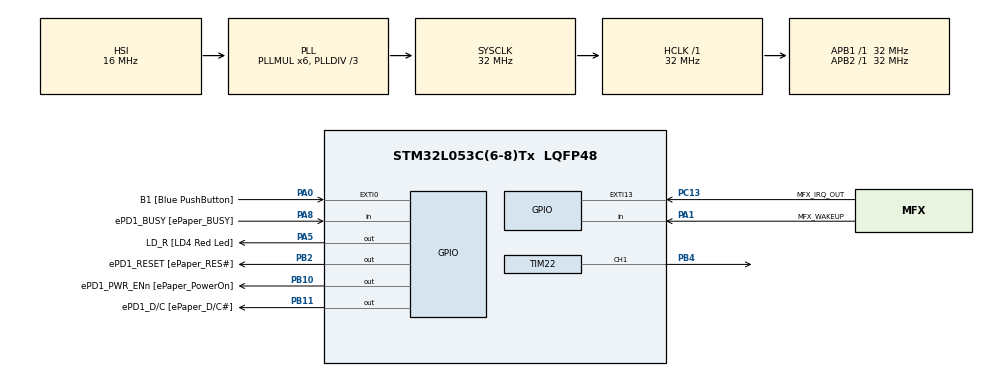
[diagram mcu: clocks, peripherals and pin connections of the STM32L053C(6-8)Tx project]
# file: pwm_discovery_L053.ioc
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Mcu.Family=STM32L0
Mcu.Name=STM32L053C(6-8)Tx
Mcu.Package=LQFP48
PA0.GPIO_Label=B1 [Blue PushButton]
PA0.GPIO_ModeDefaultEXTI=GPIO_MODE_EVT_RISING
PA0.GPIO_PuPd=GPIO_NOPULL
PA0.Signal=GPXTI0
PA1.GPIO_Label=MFX_WAKEUP
PA1.Signal=GPIO_Input
PA10.GPIO_Label=USART_RX
PA10.Signal=USART1_RX
PA11.GPIO_Label=USB1_DM
PA11.Signal=USB_DM
PA12.GPIO_Label=USB1_DP
PA12.Signal=USB_DP
PA13.GPIO_Label=SWDIO
PA13.Signal=SYS_SWDIO
PA15.GPIO_Label=ePD1_CS [ePaper_CS\#]
PA15.GPIO_Mode=GPIO_MODE_AF_PP
PA15.GPIO_PuPd=GPIO_NOPULL
PA15.GPIO_Speed=GPIO_SPEED_LOW
PA15.Signal=SPI1_NSS
PA2.Signal=TSC_G1_IO3
PA3.Signal=TSC_G1_IO4
PA5.GPIO_Label=LD_R [LD4 Red Led]
PA5.GPIO_ModeDefaultOutputPP=GPIO_MODE_OUTPUT_PP
PA5.GPIO_PuPd=GPIO_NOPULL
PA5.GPIO_Speed=GPIO_SPEED_LOW
PA5.Signal=GPIO_Output
PA6.Signal=TSC_G2_IO3
PA7.Signal=TSC_G2_IO4
PA8.GPIO_Label=ePD1_BUSY [ePaper_BUSY]
PA8.GPIO_Mode=GPIO_MODE_INPUT
PA8.GPIO_PuPd=GPIO_NOPULL
PA8.Signal=GPIO_Input
PA9.GPIO_Label=USART_TX
PA9.Signal=USART1_TX
PB0.Signal=TSC_G3_IO2
PB1.Signal=TSC_G3_IO3
PB10.GPIO_Label=ePD1_PWR_ENn [ePaper_PowerOn]
PB10.GPIO_ModeDefaultOutputPP=GPIO_MODE_OUTPUT_PP
PB10.GPIO_PuPd=GPIO_NOPULL
PB10.GPIO_Speed=GPIO_SPEED_LOW
PB10.Signal=GPIO_Output
PB11.GPIO_Label=ePD1_D/C [ePaper_D/C\#]
PB11.GPIO_ModeDefaultOutputPP=GPIO_MODE_OUTPUT_PP
PB11.GPIO_PuPd=GPIO_NOPULL
PB11.GPIO_Speed=GPIO_SPEED_LOW
PB11.Signal=GPIO_Output
PB12.GPIO_Label=NFC_NSS
PB12.Signal=SPI2_NSS
PB13.GPIO_Label=NFC_SCK
PB13.Signal=SPI2_SCK
PB14.GPIO_Label=NFC_MISO
PB14.Signal=SPI2_MISO
PB15.GPIO_Label=NFC_MOSI
PB15.Signal=SPI2_MOSI
PB2.GPIO_Label=ePD1_RESET [ePaper_RES\#]
PB2.GPIO_ModeDefaultOutputPP=GPIO_MODE_OUTPUT_PP
PB2.GPIO_PuPd=GPIO_NOPULL
PB2.GPIO_Speed=GPIO_SPEED_LOW
PB2.Signal=GPIO_Output
PB3.GPIO_Label=ePD1_SCK [ePaper_SCK]
PB3.GPIO_Mode=GPIO_MODE_AF_PP
PB3.GPIO_PuPd=GPIO_NOPULL
PB3.GPIO_Speed=GPIO_SPEED_LOW
PB3.Signal=SPI1_SCK
PB4.Signal=S_TIM22_CH1
PB5.GPIO_Label=ePD1_MOSI [ePaper_MOSI]
PB5.GPIO_Mode=GPIO_MODE_AF_PP
PB5.GPIO_PuPd=GPIO_NOPULL
PB5.GPIO_Speed=GPIO_SPEED_LOW
PB5.Signal=SPI1_MOSI
PB8.GPIO_Label=MFX_I2C_SCL
PB8.Signal=I2C1_SCL
PB9.GPIO_Label=MFX_I2C_SDA
PB9.Signal=I2C1_SDA
PC13.GPIO_Label=MFX_IRQ_OUT
PC13.Signal=GPXTI13
PC14-OSC32_IN.GPIO_Label=PC14-OSC32_IN
PC14-OSC32_IN.Signal=RCC_OSC32_IN
PC15-OSC32_OUT.GPIO_Label=PC15-OSC32_OUT
PC15-OSC32_OUT.Signal=RCC_OSC32_OUT
PH0-OSC_IN.GPIO_Label=MCO
PH0-OSC_IN.Signal=RCC_OSC_IN
ProjectManager.TargetToolchain=MDK-ARM V5
RCC.AHBFreq_Value=32000000
RCC.APB1Freq_Value=32000000
RCC.APB1TimFreq_Value=32000000
RCC.APB2Freq_Value=32000000
RCC.APB2TimFreq_Value=32000000
RCC.HCLKFreq_Value=32000000
RCC.HSE_VALUE=8000000
RCC.HSI16_VALUE=16000000
RCC.HSI48MClockSelection=RCC_USBCLKSOURCE_HSI48
RCC.HSI48_VALUE=48000000
RCC.HSI_VALUE=16000000
RCC.LSE_VALUE=32768
RCC.MSI_VALUE=2097000
RCC.PLLDIV=RCC_PLLDIV_3
RCC.PLLMUL=RCC_PLLMUL_6
RCC.RTCClockSelectionVirtual=RCC_RTCCLKSOURCE_LSE
RCC.SYSCLKFreq_VALUE=32000000
RCC.SYSCLKSource=RCC_SYSCLKSOURCE_PLLCLK
RCC.VCOOutputFreq_Value=96000000
SH.S_TIM22_CH1.0=TIM22_CH1,PWM Generation1 CH1
TIM22.Period=200
TIM22.Prescaler=32000
VP_TIM22_VS_ClockSourceINT.Mode=Internal
board=STM32L0538DISCOVERY

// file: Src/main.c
/**
  ******************************************************************************
  * File Name          : main.c
  * Description        : Main program body
  ******************************************************************************
  *
  * COPYRIGHT(c) 2015 STMicroelectronics
  *
  * Redistribution and use in source and binary forms, with or without modification,
  * are permitted provided that the following conditions are met:
  *   1. Redistributions of source code must retain the above copyright notice,
  *      this list of conditions and the following disclaimer.
  *   2. Redistributions in binary form must reproduce the above copyright notice,
  *      this list of conditions and the following disclaimer in the documentation
  *      and/or other materials provided with the distribution.
  *   3. Neither the name of STMicroelectronics nor the names of its contributors
  *      may be used to endorse or promote products derived from this software
  *      without specific prior written permission.
  *
  * THIS SOFTWARE IS PROVIDED BY THE COPYRIGHT HOLDERS AND CONTRIBUTORS "AS IS"
  * AND ANY EXPRESS OR IMPLIED WARRANTIES, INCLUDING, BUT NOT LIMITED TO, THE
  * IMPLIED WARRANTIES OF MERCHANTABILITY AND FITNESS FOR A PARTICULAR PURPOSE ARE
  * DISCLAIMED. IN NO EVENT SHALL THE COPYRIGHT HOLDER OR CONTRIBUTORS BE LIABLE
  * FOR ANY DIRECT, INDIRECT, INCIDENTAL, SPECIAL, EXEMPLARY, OR CONSEQUENTIAL
  * DAMAGES (INCLUDING, BUT NOT LIMITED TO, PROCUREMENT OF SUBSTITUTE GOODS OR
  * SERVICES; LOSS OF USE, DATA, OR PROFITS; OR BUSINESS INTERRUPTION) HOWEVER
  * CAUSED AND ON ANY THEORY OF LIABILITY, WHETHER IN CONTRACT, STRICT LIABILITY,
  * OR TORT (INCLUDING NEGLIGENCE OR OTHERWISE) ARISING IN ANY WAY OUT OF THE USE
  * OF THIS SOFTWARE, EVEN IF ADVISED OF THE POSSIBILITY OF SUCH DAMAGE.
  *
  ******************************************************************************
  */
#include "stm32l0xx_hal.h"

TIM_HandleTypeDef htim22;

/* USER CODE BEGIN PV */
/* Private variables ---------------------------------------------------------*/
int pwm = 0;
/* USER CODE END PV */

void SystemClock_Config(void);
static void MX_GPIO_Init(void);
static void MX_TIM22_Init(void);

/* USER CODE BEGIN PFP */
/* Private function prototypes -----------------------------------------------*/

/* USER CODE END PFP */

/* USER CODE BEGIN 0 */
void HAL_TIM_PeriodElapsedCallback(TIM_HandleTypeDef *htim)
{
}
/* USER CODE END 0 */

int main(void)
{

  /* MCU Configuration----------------------------------------------------------*/

  /* Reset of all peripherals, Initializes the Flash interface and the Systick. */
  HAL_Init();

  /* Configure the system clock */
  SystemClock_Config();

  /* Initialize all configured peripherals */
  MX_GPIO_Init();
  MX_TIM22_Init();

  /* USER CODE BEGIN 2 */
  HAL_TIM_PWM_Start(&htim22, TIM_CHANNEL_1);
  /* USER CODE END 2 */

  /* Infinite loop */
  while (1)
  {

  /* USER CODE BEGIN 3 */

    __HAL_TIM_SetCompare(&htim22, TIM_CHANNEL_1, 150);
    HAL_Delay(4000);
    __HAL_TIM_SetCompare(&htim22, TIM_CHANNEL_1, 50);
    HAL_Delay(4000);

  }
  /* USER CODE END 3 */

}

/** System Clock Configuration
*/
void SystemClock_Config(void)
{

  RCC_OscInitTypeDef RCC_OscInitStruct;
  RCC_ClkInitTypeDef RCC_ClkInitStruct;

  __PWR_CLK_ENABLE();

  __HAL_PWR_VOLTAGESCALING_CONFIG(PWR_REGULATOR_VOLTAGE_SCALE1);

  RCC_OscInitStruct.OscillatorType = RCC_OSCILLATORTYPE_HSI;
  RCC_OscInitStruct.HSIState = RCC_HSI_ON;
  RCC_OscInitStruct.HSICalibrationValue = 16;
  RCC_OscInitStruct.PLL.PLLState = RCC_PLL_ON;
  RCC_OscInitStruct.PLL.PLLSource = RCC_PLLSOURCE_HSI;
  RCC_OscInitStruct.PLL.PLLMUL = RCC_PLLMUL_6;
  RCC_OscInitStruct.PLL.PLLDIV = RCC_PLLDIV_3;
  HAL_RCC_OscConfig(&RCC_OscInitStruct);

  RCC_ClkInitStruct.ClockType = RCC_CLOCKTYPE_SYSCLK;
  RCC_ClkInitStruct.SYSCLKSource = RCC_SYSCLKSOURCE_PLLCLK;
  RCC_ClkInitStruct.AHBCLKDivider = RCC_SYSCLK_DIV1;
  RCC_ClkInitStruct.APB1CLKDivider = RCC_HCLK_DIV1;
  RCC_ClkInitStruct.APB2CLKDivider = RCC_HCLK_DIV1;
  HAL_RCC_ClockConfig(&RCC_ClkInitStruct, FLASH_LATENCY_1);

  HAL_SYSTICK_Config(HAL_RCC_GetHCLKFreq()/1000);

  HAL_SYSTICK_CLKSourceConfig(SYSTICK_CLKSOURCE_HCLK);

  /* SysTick_IRQn interrupt configuration */
  HAL_NVIC_SetPriority(SysTick_IRQn, 0, 0);
}

/* TIM22 init function */
void MX_TIM22_Init(void)
{

  TIM_ClockConfigTypeDef sClockSourceConfig;
  TIM_MasterConfigTypeDef sMasterConfig;
  TIM_OC_InitTypeDef sConfigOC;

  htim22.Instance = TIM22;
  htim22.Init.Prescaler = 320;
  htim22.Init.CounterMode = TIM_COUNTERMODE_UP;
  htim22.Init.Period = 200;
  htim22.Init.ClockDivision = TIM_CLOCKDIVISION_DIV1;
  HAL_TIM_Base_Init(&htim22);

  sClockSourceConfig.ClockSource = TIM_CLOCKSOURCE_INTERNAL;
  HAL_TIM_ConfigClockSource(&htim22, &sClockSourceConfig);

  HAL_TIM_PWM_Init(&htim22);

  sMasterConfig.MasterOutputTrigger = TIM_TRGO_RESET;
  sMasterConfig.MasterSlaveMode = TIM_MASTERSLAVEMODE_DISABLE;
  HAL_TIMEx_MasterConfigSynchronization(&htim22, &sMasterConfig);

  sConfigOC.OCMode = TIM_OCMODE_PWM1;
  sConfigOC.Pulse = 0;
  sConfigOC.OCPolarity = TIM_OCPOLARITY_HIGH;
  sConfigOC.OCFastMode = TIM_OCFAST_DISABLE;
  HAL_TIM_PWM_ConfigChannel(&htim22, &sConfigOC, TIM_CHANNEL_1);

}

/** Configure pins as
        * Analog
        * Input
        * Output
        * EVENT_OUT
        * EXTI
     PA2   ------> TSC_G1_IO3
     PA3   ------> TSC_G1_IO4
     PA6   ------> TSC_G2_IO3
     PA7   ------> TSC_G2_IO4
     PB0   ------> TSC_G3_IO2
     PB1   ------> TSC_G3_IO3
     PB12   ------> SPI2_NSS
     PB13   ------> SPI2_SCK
     PB14   ------> SPI2_MISO
     PB15   ------> SPI2_MOSI
     PA9   ------> USART1_TX
     PA10   ------> USART1_RX
     PA15   ------> SPI1_NSS
     PB3   ------> SPI1_SCK
     PB5   ------> SPI1_MOSI
     PB8   ------> I2C1_SCL
     PB9   ------> I2C1_SDA
*/
void MX_GPIO_Init(void)
{

  GPIO_InitTypeDef GPIO_InitStruct;

  /* GPIO Ports Clock Enable */
  __GPIOC_CLK_ENABLE();
  __GPIOH_CLK_ENABLE();
  __GPIOA_CLK_ENABLE();
  __GPIOB_CLK_ENABLE();

  /*Configure GPIO pin : MFX_IRQ_OUT_Pin */
  GPIO_InitStruct.Pin = MFX_IRQ_OUT_Pin;
  GPIO_InitStruct.Mode = GPIO_MODE_IT_RISING;
  GPIO_InitStruct.Pull = GPIO_NOPULL;
  HAL_GPIO_Init(MFX_IRQ_OUT_GPIO_Port, &GPIO_InitStruct);

  /*Configure GPIO pin : B1_Pin */
  GPIO_InitStruct.Pin = B1_Pin;
  GPIO_InitStruct.Mode = GPIO_MODE_EVT_RISING;
  GPIO_InitStruct.Pull = GPIO_NOPULL;
  HAL_GPIO_Init(B1_GPIO_Port, &GPIO_InitStruct);

  /*Configure GPIO pins : MFX_WAKEUP_Pin ePD1_BUSY_Pin */
  GPIO_InitStruct.Pin = MFX_WAKEUP_Pin|ePD1_BUSY_Pin;
  GPIO_InitStruct.Mode = GPIO_MODE_INPUT;
  GPIO_InitStruct.Pull = GPIO_NOPULL;
  HAL_GPIO_Init(GPIOA, &GPIO_InitStruct);

  /*Configure GPIO pins : PA2 PA3 PA6 PA7 */
  GPIO_InitStruct.Pin = GPIO_PIN_2|GPIO_PIN_3|GPIO_PIN_6|GPIO_PIN_7;
  GPIO_InitStruct.Mode = GPIO_MODE_AF_PP;
  GPIO_InitStruct.Pull = GPIO_NOPULL;
  GPIO_InitStruct.Speed = GPIO_SPEED_LOW;
  GPIO_InitStruct.Alternate = GPIO_AF3_TSC;
  HAL_GPIO_Init(GPIOA, &GPIO_InitStruct);

  /*Configure GPIO pin : LD_R_Pin */
  GPIO_InitStruct.Pin = LD_R_Pin;
  GPIO_InitStruct.Mode = GPIO_MODE_OUTPUT_PP;
  GPIO_InitStruct.Pull = GPIO_NOPULL;
  GPIO_InitStruct.Speed = GPIO_SPEED_LOW;
  HAL_GPIO_Init(LD_R_GPIO_Port, &GPIO_InitStruct);

  /*Configure GPIO pins : PB0 PB1 */
  GPIO_InitStruct.Pin = GPIO_PIN_0|GPIO_PIN_1;
  GPIO_InitStruct.Mode = GPIO_MODE_AF_PP;
  GPIO_InitStruct.Pull = GPIO_NOPULL;
  GPIO_InitStruct.Speed = GPIO_SPEED_LOW;
  GPIO_InitStruct.Alternate = GPIO_AF3_TSC;
  HAL_GPIO_Init(GPIOB, &GPIO_InitStruct);

  /*Configure GPIO pins : ePD1_RESET_Pin ePD1_PWR_ENn_Pin ePD1_D_C_Pin */
  GPIO_InitStruct.Pin = ePD1_RESET_Pin|ePD1_PWR_ENn_Pin|ePD1_D_C_Pin;
  GPIO_InitStruct.Mode = GPIO_MODE_OUTPUT_PP;
  GPIO_InitStruct.Pull = GPIO_NOPULL;
  GPIO_InitStruct.Speed = GPIO_SPEED_LOW;
  HAL_GPIO_Init(GPIOB, &GPIO_InitStruct);

  /*Configure GPIO pins : NFC_NSS_Pin NFC_SCK_Pin NFC_MISO_Pin NFC_MOSI_Pin */
  GPIO_InitStruct.Pin = NFC_NSS_Pin|NFC_SCK_Pin|NFC_MISO_Pin|NFC_MOSI_Pin;
  GPIO_InitStruct.Mode = GPIO_MODE_AF_PP;
  GPIO_InitStruct.Pull = GPIO_NOPULL;
  GPIO_InitStruct.Speed = GPIO_SPEED_HIGH;
  GPIO_InitStruct.Alternate = GPIO_AF0_SPI2;
  HAL_GPIO_Init(GPIOB, &GPIO_InitStruct);

  /*Configure GPIO pins : USART_TX_Pin USART_RX_Pin */
  GPIO_InitStruct.Pin = USART_TX_Pin|USART_RX_Pin;
  GPIO_InitStruct.Mode = GPIO_MODE_AF_PP;
  GPIO_InitStruct.Pull = GPIO_NOPULL;
  GPIO_InitStruct.Speed = GPIO_SPEED_HIGH;
  GPIO_InitStruct.Alternate = GPIO_AF4_USART1;
  HAL_GPIO_Init(GPIOA, &GPIO_InitStruct);

  /*Configure GPIO pin : ePD1_CS_Pin */
  GPIO_InitStruct.Pin = ePD1_CS_Pin;
  GPIO_InitStruct.Mode = GPIO_MODE_AF_PP;
  GPIO_InitStruct.Pull = GPIO_NOPULL;
  GPIO_InitStruct.Speed = GPIO_SPEED_LOW;
  GPIO_InitStruct.Alternate = GPIO_AF0_SPI1;
  HAL_GPIO_Init(ePD1_CS_GPIO_Port, &GPIO_InitStruct);

  /*Configure GPIO pins : ePD1_SCK_Pin ePD1_MOSI_Pin */
  GPIO_InitStruct.Pin = ePD1_SCK_Pin|ePD1_MOSI_Pin;
  GPIO_InitStruct.Mode = GPIO_MODE_AF_PP;
  GPIO_InitStruct.Pull = GPIO_NOPULL;
  GPIO_InitStruct.Speed = GPIO_SPEED_LOW;
  GPIO_InitStruct.Alternate = GPIO_AF0_SPI1;
  HAL_GPIO_Init(GPIOB, &GPIO_InitStruct);

  /*Configure GPIO pins : MFX_I2C_SCL_Pin MFX_I2C_SDA_Pin */
  GPIO_InitStruct.Pin = MFX_I2C_SCL_Pin|MFX_I2C_SDA_Pin;
  GPIO_InitStruct.Mode = GPIO_MODE_AF_OD;
  GPIO_InitStruct.Pull = GPIO_PULLUP;
  GPIO_InitStruct.Speed = GPIO_SPEED_HIGH;
  GPIO_InitStruct.Alternate = GPIO_AF4_I2C1;
  HAL_GPIO_Init(GPIOB, &GPIO_InitStruct);

}

/************************ (C) COPYRIGHT STMicroelectronics *****END OF FILE****/
